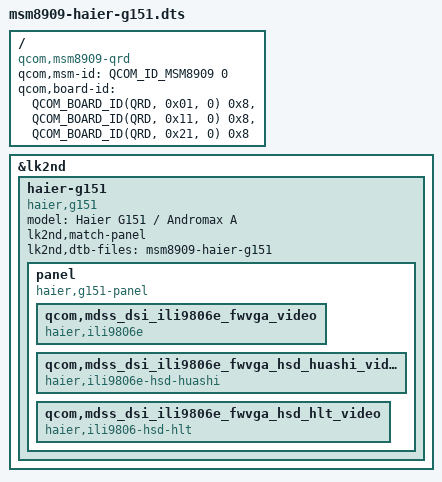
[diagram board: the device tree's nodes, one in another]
// SPDX-License-Identifier: BSD-3-Clause

#include <skeleton32.dtsi>
#include <lk2nd.dtsi>

/ {
	qcom,msm-id = <QCOM_ID_MSM8909 0>;
	qcom,board-id = <QCOM_BOARD_ID(QRD, 0x01, 0) 0x8>,
			<QCOM_BOARD_ID(QRD, 0x11, 0) 0x8>,
			<QCOM_BOARD_ID(QRD, 0x21, 0) 0x8>;
	compatible = "qcom,msm8909-qrd", "qcom,msm8909", "qcom,qrd";
};

&lk2nd {
	haier-g151 {
		model = "Haier G151 / Andromax A";
		compatible = "haier,g151";
		lk2nd,match-panel;
		lk2nd,dtb-files = "msm8909-haier-g151";

    panel {
        compatible = "haier,g151-panel";

    qcom,mdss_dsi_ili9806e_fwvga_video {
        compatible = "haier,ili9806e";
      };

    qcom,mdss_dsi_ili9806e_fwvga_hsd_huashi_video {
        compatible = "haier,ili9806e-hsd-huashi";
      };

    qcom,mdss_dsi_ili9806e_fwvga_hsd_hlt_video {
        compatible = "haier,ili9806-hsd-hlt";
                        };
                };
        };
};
